# STM32WL5x_CM0P register map
File version: 1.9
CPU: CM0 r0p1, little endian, MPU, no FPU, 4 interrupt priority bits
Registers are 32-bit, read-write, reset 0x0 unless marked. A register's access mark holds for its fields unless they carry their own. Offsets are from the block's base; [hi:lo] are bit positions; 'fields as' and 'values as' point back to an identical list.

## RTC — Real-time clock
Base 0x40002800
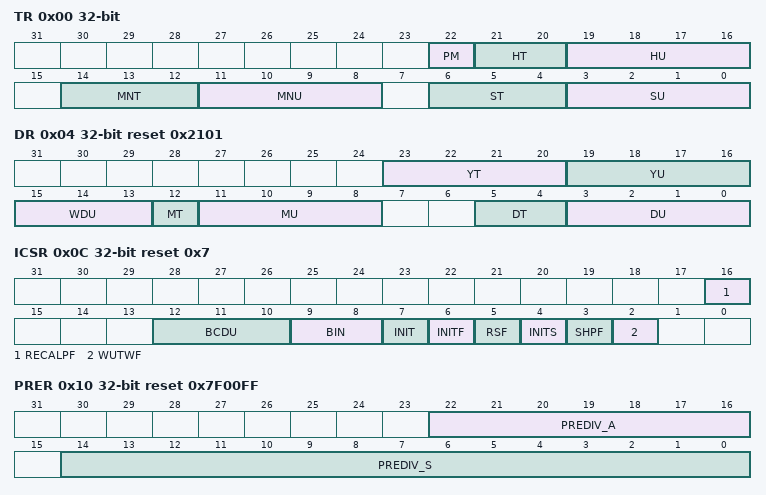
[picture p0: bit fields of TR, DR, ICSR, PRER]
0x00 TR
  [22] PM — AM/PM notation
  [21:20] HT — Hour tens in BCD format
  [19:16] HU — Hour units in BCD format
  [14:12] MNT — Minute tens in BCD format
  [11:8] MNU — Minute units in BCD format
  [6:4] ST — Second tens in BCD format
  [3:0] SU — Second units in BCD format
0x04 DR reset 0x2101
  [23:20] YT — Year tens in BCD format
  [19:16] YU — Year units in BCD format
  [15:13] WDU — Week day units
  [12] MT — Month tens in BCD format
  [11:8] MU — Month units in BCD format
  [5:4] DT — Date tens in BCD format
  [3:0] DU — Date units in BCD format
0x08 SSR ro
  [31:0] SS — Synchronous binary counter
0x0C ICSR access per field reset 0x7
  [16] RECALPF ro — Recalibration pending Flag
  [12:10] BCDU rw — BCD update
  [9:8] BIN rw — Binary mode
  [7] INIT rw — Initialization mode
  [6] INITF ro — Initialization flag
  [5] RSF rw — Registers synchronization flag
  [4] INITS ro — Initialization status flag
  [3] SHPF ro — Shift operation pending
  [2] WUTWF ro — Wakeup timer write flag
0x10 PRER reset 0x7F00FF
  [22:16] PREDIV_A — Asynchronous prescaler factor
  [14:0] PREDIV_S — Synchronous prescaler factor
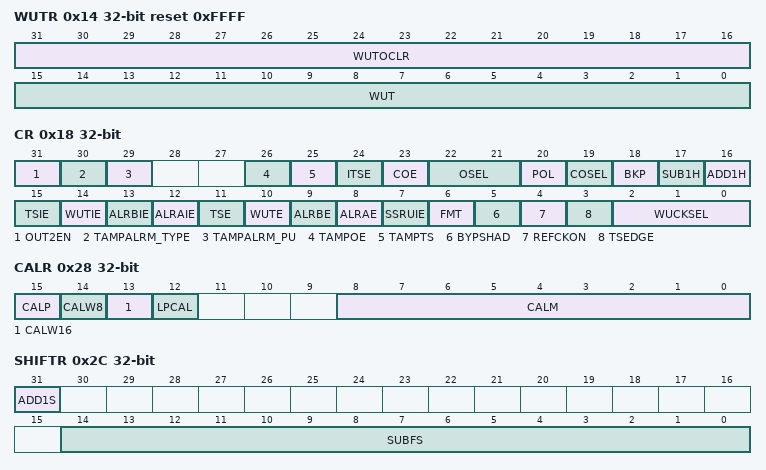
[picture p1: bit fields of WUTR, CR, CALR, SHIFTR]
0x14 WUTR reset 0xFFFF
  [31:16] WUTOCLR — Wakeup auto-reload output clear value
  [15:0] WUT — Wakeup auto-reload value bits
0x18 CR access per field
  [31] OUT2EN rw — RTC_OUT2 output enable
  [30] TAMPALRM_TYPE rw — TAMPALRM output type
  [29] TAMPALRM_PU rw — TAMPALRM pull-up enable
  [26] TAMPOE rw — Tamper detection output enable on TAMPALRM
  [25] TAMPTS rw — Activate timestamp on tamper detection event
  [24] ITSE rw — timestamp on internal event enable
  [23] COE rw — Calibration output enable
  [22:21] OSEL rw — Output selection
  [20] POL rw — Output polarity
  [19] COSEL rw — Calibration output selection
  [18] BKP rw — Backup
  [17] SUB1H wo — Subtract 1 hour (winter time change)
  [16] ADD1H wo — Add 1 hour (summer time change)
  [15] TSIE rw — Timestamp interrupt enable
  [14] WUTIE rw — Wakeup timer interrupt enable
  [13] ALRBIE rw — Alarm B interrupt enable
  [12] ALRAIE rw — Alarm A interrupt enable
  [11] TSE rw — timestamp enable
  [10] WUTE rw — Wakeup timer enable
  [9] ALRBE rw — Alarm B enable
  [8] ALRAE rw — Alarm A enable
  [7] SSRUIE rw — SSR underflow interrupt enable
  [6] FMT rw — Hour format
  [5] BYPSHAD rw — Bypass the shadow registers
  [4] REFCKON rw — RTC_REFIN reference clock detection enable (50 or 60 Hz)
  [3] TSEDGE rw — Timestamp event active edge
  [2:0] WUCKSEL rw — Wakeup clock selection
0x24 WPR wo — write protection register
  [7:0] KEY — Write protection key
0x28 CALR
  [15] CALP — Use an 8-second calibration cycle period
  [14] CALW8 — Use a 16-second calibration cycle period
  [13] CALW16
  [12] LPCAL — Calibration low-power mode
  [8:0] CALM — Calibration minus
0x2C SHIFTR wo
  [31] ADD1S — Add one second
  [14:0] SUBFS — Subtract a fraction of a second
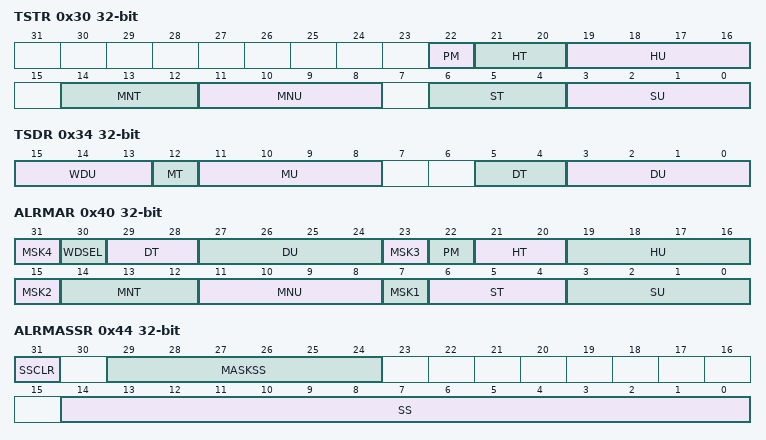
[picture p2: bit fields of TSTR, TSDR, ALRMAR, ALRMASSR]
0x30 TSTR ro
  [22] PM — AM/PM notation
  [21:20] HT — Hour tens in BCD format.
  [19:16] HU — Hour units in BCD format.
  [14:12] MNT — Minute tens in BCD format.
  [11:8] MNU — Minute units in BCD format.
  [6:4] ST — Second tens in BCD format.
  [3:0] SU — Second units in BCD format.
0x34 TSDR ro
  [15:13] WDU — Week day units
  [12] MT — Month tens in BCD format
  [11:8] MU — Month units in BCD format
  [5:4] DT — Date tens in BCD format
  [3:0] DU — Date units in BCD format
0x38 TSSSR ro
  [31:0] SS — Sub second value
0x40 ALRMAR
  [31] MSK4 — Alarm A date mask
  [30] WDSEL — Week day selection
  [29:28] DT — Date tens in BCD format
  [27:24] DU — Date units or day in BCD format
  [23] MSK3 — Alarm A hours mask
  [22] PM — AM/PM notation
  [21:20] HT — Hour tens in BCD format
  [19:16] HU — Hour units in BCD format
  [15] MSK2 — Alarm A minutes mask
  [14:12] MNT — Minute tens in BCD format
  [11:8] MNU — Minute units in BCD format
  [7] MSK1 — Alarm A seconds mask
  [6:4] ST — Second tens in BCD format.
  [3:0] SU — Second units in BCD format.
0x44 ALRMASSR
  [31] SSCLR — Clear synchronous counter on alarm (Binary mode only)
  [29:24] MASKSS — Mask the most-significant bits starting at this bit
  [14:0] SS — Sub seconds value
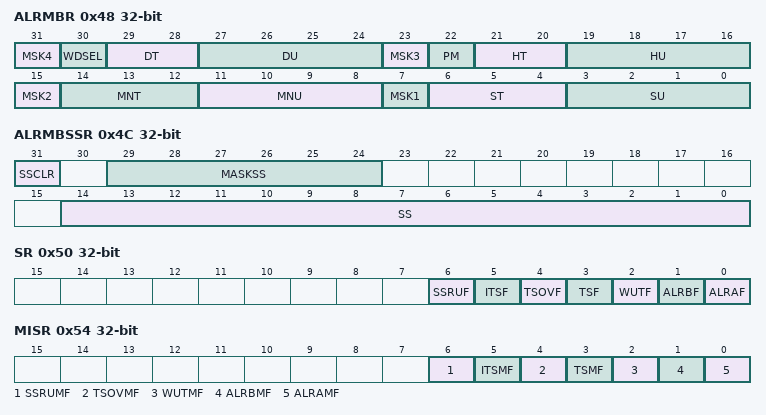
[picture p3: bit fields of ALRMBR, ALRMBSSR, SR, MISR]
0x48 ALRMBR
  [31] MSK4 — Alarm B date mask
  [30] WDSEL — Week day selection
  [29:28] DT — Date tens in BCD format
  [27:24] DU — Date units or day in BCD format
  [23] MSK3 — Alarm B hours mask
  [22] PM — AM/PM notation
  [21:20] HT — Hour tens in BCD format
  [19:16] HU — Hour units in BCD format
  [15] MSK2 — Alarm B minutes mask
  [14:12] MNT — Minute tens in BCD format
  [11:8] MNU — Minute units in BCD format
  [7] MSK1 — Alarm B seconds mask
  [6:4] ST — Second tens in BCD format
  [3:0] SU — Second units in BCD format
0x4C ALRMBSSR
  fields as ALRMASSR
0x50 SR ro
  [6] SSRUF — SSR underflow flag
  [5] ITSF — Internal timestamp flag
  [4] TSOVF — Timestamp overflow flag
  [3] TSF — Timestamp flag
  [2] WUTF — Wakeup timer flag
  [1] ALRBF — Alarm B flag
  [0] ALRAF — Alarm A flag
0x54 MISR ro
  [6] SSRUMF — SSR underflow masked flag
  [5] ITSMF — Internal timestamp masked flag
  [4] TSOVMF — Timestamp overflow masked flag
  [3] TSMF — Timestamp masked flag
  [2] WUTMF — Wakeup timer masked flag
  [1] ALRBMF — Alarm B masked flag
  [0] ALRAMF — Alarm A masked flag
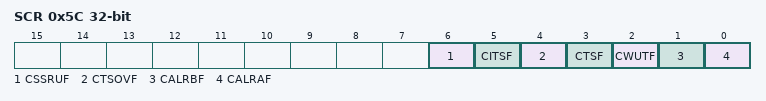
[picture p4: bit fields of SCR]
0x5C SCR wo
  [6] CSSRUF — Clear SSR underflow flag
  [5] CITSF — Clear internal timestamp flag
  [4] CTSOVF — Clear timestamp overflow flag
  [3] CTSF — Clear timestamp flag
  [2] CWUTF — Clear wakeup timer flag
  [1] CALRBF — Clear alarm B flag
  [0] CALRAF — Clear alarm A flag
0x70 ALRABINR — RTC alarm A binary mode register
  [31:0] SS — Synchronous counter alarm value in Binary mode
0x74 ALRBBINR — RTC alarm B binary mode register
  [31:0] SS — Synchronous counter alarm value in Binary mode
